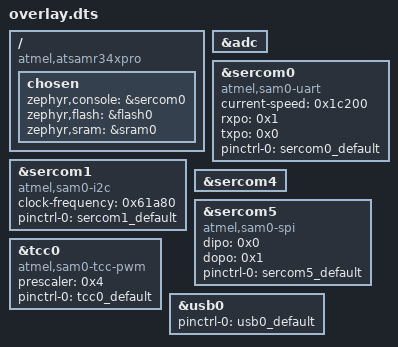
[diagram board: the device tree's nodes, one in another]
/ {
	compatible = "atmel,atsamr34xpro", "atmel,samr34", "atmel,samr34j18b";
	chosen {
		zephyr,console = &sercom0;
		zephyr,flash = &flash0;
		zephyr,sram = &sram0;
	};
};
&adc{
	status = "okay";
};
&sercom0{
	compatible = "atmel,sam0-uart";
	status = "okay";
	current-speed = < 0x1c200 >;
	rxpo = < 0x1 >;
	txpo = < 0x0 >;
	pinctrl-0 = < &sercom0_default >;
	pinctrl-names = "default";
};
&sercom1{
	compatible = "atmel,sam0-i2c";
	status = "okay";
	clock-frequency = < 0x61a80 >;
	#address-cells = < 0x1 >;
	#size-cells = < 0x0 >;
	pinctrl-0 = < &sercom1_default >;
	pinctrl-names = "default";
};
&sercom4{
	status = "okay";
};
&sercom5{
	compatible = "atmel,sam0-spi";
	status = "okay";
	dipo = < 0x0 >;
	dopo = < 0x1 >;
	#address-cells = < 0x1 >;
	#size-cells = < 0x0 >;
	pinctrl-0 = < &sercom5_default >;
	pinctrl-names = "default";
};
&tcc0{
	compatible = "atmel,sam0-tcc-pwm";
	status = "okay";
	prescaler = < 0x4 >;
	#pwm-cells = < 0x2 >;
	pinctrl-0 = < &tcc0_default >;
	pinctrl-names = "default";
};
&usb0{
	status = "okay";
	pinctrl-0 = < &usb0_default >;
	pinctrl-names = "default";
};
